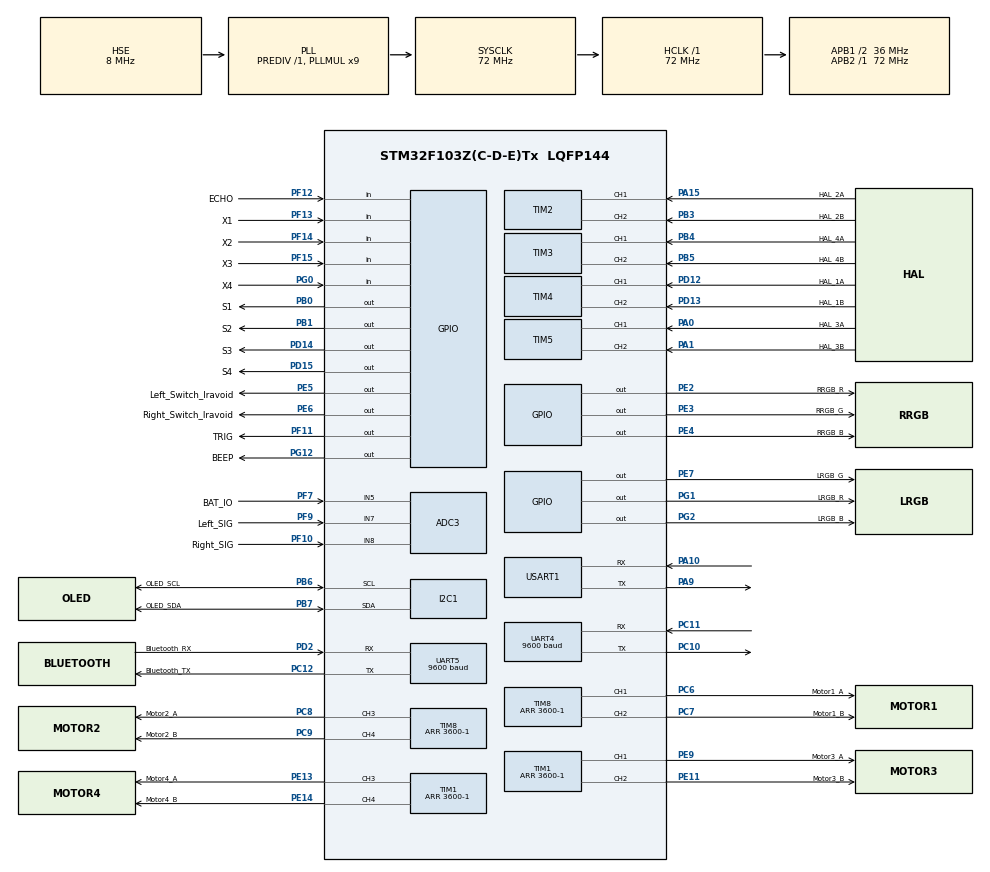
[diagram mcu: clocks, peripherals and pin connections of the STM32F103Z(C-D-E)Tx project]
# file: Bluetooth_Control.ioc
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ADC3.Channel-0\#ChannelRegularConversion=ADC_CHANNEL_5
ADC3.NbrOfConversionFlag=1
ADC3.Rank-0\#ChannelRegularConversion=1
ADC3.SamplingTime-0\#ChannelRegularConversion=ADC_SAMPLETIME_239CYCLES_5
Dma.Request0=USART1_TX
Dma.USART1_TX.0.Direction=DMA_MEMORY_TO_PERIPH
Dma.USART1_TX.0.Instance=DMA1_Channel4
Dma.USART1_TX.0.MemDataAlignment=DMA_MDATAALIGN_BYTE
Dma.USART1_TX.0.MemInc=DMA_MINC_ENABLE
Dma.USART1_TX.0.Mode=DMA_NORMAL
Dma.USART1_TX.0.PeriphDataAlignment=DMA_PDATAALIGN_BYTE
Dma.USART1_TX.0.PeriphInc=DMA_PINC_DISABLE
Dma.USART1_TX.0.Priority=DMA_PRIORITY_LOW
I2C1.I2C_Mode=I2C_Fast
Mcu.Family=STM32F1
Mcu.Name=STM32F103Z(C-D-E)Tx
Mcu.Package=LQFP144
NVIC.DMA1_Channel4_IRQn=true\:1\:0\:true\:false\:true\:false\:true\:true
NVIC.PriorityGroup=NVIC_PRIORITYGROUP_2
NVIC.TIM6_IRQn=true\:2\:1\:true\:false\:true\:true\:true\:true
NVIC.TIM7_IRQn=true\:2\:2\:true\:false\:true\:true\:true\:true
NVIC.UART4_IRQn=true\:1\:0\:true\:false\:true\:true\:true\:true
NVIC.UART5_IRQn=true\:1\:0\:true\:false\:true\:true\:true\:true
NVIC.USART1_IRQn=true\:1\:0\:true\:false\:true\:true\:true\:true
OSC_IN.Mode=HSE-External-Oscillator
OSC_IN.Signal=RCC_OSC_IN
OSC_OUT.Mode=HSE-External-Oscillator
OSC_OUT.Signal=RCC_OSC_OUT
PA0-WKUP.GPIO_Label=HAL_3A
PA0-WKUP.Signal=S_TIM5_CH1
PA1.GPIO_Label=HAL_3B
PA1.Signal=S_TIM5_CH2
PA10.Mode=Asynchronous
PA10.Signal=USART1_RX
PA13.Mode=Serial_Wire
PA13.Signal=SYS_JTMS-SWDIO
PA14.Mode=Serial_Wire
PA14.Signal=SYS_JTCK-SWCLK
PA15.GPIO_Label=HAL_2A
PA15.Signal=S_TIM2_CH1_ETR
PA9.Mode=Asynchronous
PA9.Signal=USART1_TX
PB0.GPIO_Label=S1
PB0.GPIO_Speed=GPIO_SPEED_FREQ_HIGH
PB0.Signal=GPIO_Output
PB1.GPIO_Label=S2
PB1.GPIO_Speed=GPIO_SPEED_FREQ_HIGH
PB1.Signal=GPIO_Output
PB3.GPIO_Label=HAL_2B
PB3.Signal=S_TIM2_CH2
PB4.GPIO_Label=HAL_4A
PB4.Signal=S_TIM3_CH1
PB5.GPIO_Label=HAL_4B
PB5.Signal=S_TIM3_CH2
PB6.GPIO_Label=OLED_SCL
PB6.Mode=I2C
PB6.Signal=I2C1_SCL
PB7.GPIO_Label=OLED_SDA
PB7.Mode=I2C
PB7.Signal=I2C1_SDA
PC10.Mode=Asynchronous
PC10.Signal=UART4_TX
PC11.Mode=Asynchronous
PC11.Signal=UART4_RX
PC12.GPIO_Label=Bluetooth_TX
PC12.Mode=Asynchronous
PC12.Signal=UART5_TX
PC6.GPIO_Label=Motor1_A
PC6.Signal=S_TIM8_CH1
PC7.GPIO_Label=Motor1_B
PC7.Signal=S_TIM8_CH2
PC8.GPIO_Label=Motor2_A
PC8.Signal=S_TIM8_CH3
PC9.GPIO_Label=Motor2_B
PC9.Signal=S_TIM8_CH4
PD12.GPIO_Label=HAL_1A
PD12.Signal=S_TIM4_CH1
PD13.GPIO_Label=HAL_1B
PD13.Signal=S_TIM4_CH2
PD14.GPIO_Label=S3
PD14.GPIO_Speed=GPIO_SPEED_FREQ_HIGH
PD14.Signal=GPIO_Output
PD15.GPIO_Label=S4
PD15.GPIO_Speed=GPIO_SPEED_FREQ_HIGH
PD15.Signal=GPIO_Output
PD2.GPIO_Label=Bluetooth_RX
PD2.Mode=Asynchronous
PD2.Signal=UART5_RX
PE11.GPIO_Label=Motor3_B
PE11.Signal=S_TIM1_CH2
PE13.GPIO_Label=Motor4_A
PE13.Signal=S_TIM1_CH3
PE14.GPIO_Label=Motor4_B
PE14.Signal=S_TIM1_CH4
PE2.GPIO_Label=RRGB_R
PE2.GPIO_Speed=GPIO_SPEED_FREQ_MEDIUM
PE2.Signal=GPIO_Output
PE3.GPIO_Label=RRGB_G
PE3.GPIO_Speed=GPIO_SPEED_FREQ_MEDIUM
PE3.Signal=GPIO_Output
PE4.GPIO_Label=RRGB_B
PE4.GPIO_Speed=GPIO_SPEED_FREQ_MEDIUM
PE4.Signal=GPIO_Output
PE5.GPIO_Label=Left_Switch_Iravoid
PE5.GPIO_Speed=GPIO_SPEED_FREQ_MEDIUM
PE5.PinState=GPIO_PIN_SET
PE5.Signal=GPIO_Output
PE6.GPIO_Label=Right_Switch_Iravoid
PE6.GPIO_Speed=GPIO_SPEED_FREQ_MEDIUM
PE6.PinState=GPIO_PIN_SET
PE6.Signal=GPIO_Output
PE7.GPIO_Label=LRGB_G
PE7.GPIO_Speed=GPIO_SPEED_FREQ_MEDIUM
PE7.Signal=GPIO_Output
PE9.GPIO_Label=Motor3_A
PE9.Signal=S_TIM1_CH1
PF10.GPIO_Label=Right_SIG
PF10.Mode=IN8
PF10.Signal=ADC3_IN8
PF11.GPIO_Label=TRIG
PF11.GPIO_Speed=GPIO_SPEED_FREQ_MEDIUM
PF11.Signal=GPIO_Output
PF12.GPIO_Label=ECHO
PF12.Signal=GPIO_Input
PF13.GPIO_Label=X1
PF13.Signal=GPIO_Input
PF14.GPIO_Label=X2
PF14.Signal=GPIO_Input
PF15.GPIO_Label=X3
PF15.Signal=GPIO_Input
PF7.GPIO_Label=BAT_IO
PF7.Mode=IN5
PF7.Signal=ADC3_IN5
PF9.GPIO_Label=Left_SIG
PF9.Mode=IN7
PF9.Signal=ADC3_IN7
PG0.GPIO_Label=X4
PG0.Signal=GPIO_Input
PG1.GPIO_Label=LRGB_R
PG1.GPIO_Speed=GPIO_SPEED_FREQ_MEDIUM
PG1.Signal=GPIO_Output
PG12.GPIO_Label=BEEP
PG12.GPIO_Speed=GPIO_SPEED_FREQ_MEDIUM
PG12.Signal=GPIO_Output
PG2.GPIO_Label=LRGB_B
PG2.GPIO_Speed=GPIO_SPEED_FREQ_MEDIUM
PG2.Signal=GPIO_Output
ProjectManager.HeapSize=0x200
ProjectManager.StackSize=0x400
ProjectManager.TargetToolchain=STM32CubeIDE
RCC.ADCPresc=RCC_ADCPCLK2_DIV6
RCC.AHBFreq_Value=72000000
RCC.APB1CLKDivider=RCC_HCLK_DIV2
RCC.APB1Freq_Value=36000000
RCC.APB1TimFreq_Value=72000000
RCC.APB2Freq_Value=72000000
RCC.APB2TimFreq_Value=72000000
RCC.HCLKFreq_Value=72000000
RCC.PLLMUL=RCC_PLL_MUL9
RCC.PLLSourceVirtual=RCC_PLLSOURCE_HSE
RCC.SYSCLKFreq_VALUE=72000000
RCC.SYSCLKSource=RCC_SYSCLKSOURCE_PLLCLK
RCC.USBFreq_Value=72000000
SH.S_TIM1_CH1.0=TIM1_CH1,PWM Generation1 CH1
SH.S_TIM1_CH2.0=TIM1_CH2,PWM Generation2 CH2
SH.S_TIM1_CH3.0=TIM1_CH3,PWM Generation3 CH3
SH.S_TIM1_CH4.0=TIM1_CH4,PWM Generation4 CH4
SH.S_TIM2_CH1_ETR.0=TIM2_CH1,Encoder_Interface
SH.S_TIM2_CH2.0=TIM2_CH2,Encoder_Interface
SH.S_TIM3_CH1.0=TIM3_CH1,Encoder_Interface
SH.S_TIM3_CH2.0=TIM3_CH2,Encoder_Interface
SH.S_TIM4_CH1.0=TIM4_CH1,Encoder_Interface
SH.S_TIM4_CH2.0=TIM4_CH2,Encoder_Interface
SH.S_TIM5_CH1.0=TIM5_CH1,Encoder_Interface
SH.S_TIM5_CH2.0=TIM5_CH2,Encoder_Interface
SH.S_TIM8_CH1.0=TIM8_CH1,PWM Generation1 CH1
SH.S_TIM8_CH2.0=TIM8_CH2,PWM Generation2 CH2
SH.S_TIM8_CH3.0=TIM8_CH3,PWM Generation3 CH3
SH.S_TIM8_CH4.0=TIM8_CH4,PWM Generation4 CH4
TIM1.AutoReloadPreload=TIM_AUTORELOAD_PRELOAD_ENABLE
TIM1.Channel-PWM\ Generation1\ CH1=TIM_CHANNEL_1
TIM1.Channel-PWM\ Generation2\ CH2=TIM_CHANNEL_2
TIM1.Channel-PWM\ Generation3\ CH3=TIM_CHANNEL_3
TIM1.Channel-PWM\ Generation4\ CH4=TIM_CHANNEL_4
TIM1.Period=3600-1
TIM2.EncoderMode=TIM_ENCODERMODE_TI12
TIM3.EncoderMode=TIM_ENCODERMODE_TI12
TIM4.EncoderMode=TIM_ENCODERMODE_TI12
TIM5.EncoderMode=TIM_ENCODERMODE_TI12
TIM6.Period=99
TIM6.Prescaler=7199
TIM7.Period=9
TIM7.Prescaler=71
TIM8.AutoReloadPreload=TIM_AUTORELOAD_PRELOAD_ENABLE
TIM8.Channel-PWM\ Generation1\ CH1=TIM_CHANNEL_1
TIM8.Channel-PWM\ Generation2\ CH2=TIM_CHANNEL_2
TIM8.Channel-PWM\ Generation3\ CH3=TIM_CHANNEL_3
TIM8.Channel-PWM\ Generation4\ CH4=TIM_CHANNEL_4
TIM8.Period=3600-1
UART4.BaudRate=9600
UART4.VirtualMode=Asynchronous
UART5.BaudRate=9600
UART5.VirtualMode=Asynchronous
USART1.VirtualMode=VM_ASYNC
VP_TIM1_VS_ClockSourceINT.Mode=Internal
VP_TIM6_VS_ClockSourceINT.Mode=Enable_Timer
VP_TIM7_VS_ClockSourceINT.Mode=Enable_Timer
VP_TIM8_VS_ClockSourceINT.Mode=Internal
board=custom

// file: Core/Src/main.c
/* USER CODE BEGIN Header */
/**
  ******************************************************************************
  * @file           : main.c
  * @brief          : Main program body
  ******************************************************************************
  * @attention
  *
  * <h2><center>&copy; Copyright (c) 2023 STMicroelectronics.
  * All rights reserved.</center></h2>
  *
  * This software component is licensed by ST under BSD 3-Clause license,
  * the "License"; You may not use this file except in compliance with the
  * License. You may obtain a copy of the License at:
  *                        opensource.org/licenses/BSD-3-Clause
  *
  ******************************************************************************
  */
/* USER CODE END Header */
#include "main.h"
#include "adc.h"
#include "dma.h"
#include "i2c.h"
#include "tim.h"
#include "usart.h"
#include "gpio.h"

/* USER CODE BEGIN Includes */
#include "bsp.h"
/* USER CODE END Includes */

void SystemClock_Config(void);

int main(void)
{

  /* USER CODE BEGIN 1 */
  /*
   * 上电第一件事: �? PC10 (UART4_TX, 连接 IMU RX) 拉高�?
   * 如果 PC10 浮空�? LOW, IMU �? RX 引脚会收到持续低电平,
   * 导致 IMU 进入 bootloader 模式而非正常运行 (LED 不闪, 不发送数�?)�?
   * 必须先开 GPIOC 时钟, 配为推挽输出, �? BSRR 置高�?
   */
  RCC->APB2ENR |= RCC_APB2ENR_IOPCEN;
  GPIOC->CRH &= ~(0xF << 8);        /* �? PC10 配置�? */
  GPIOC->CRH |=  (0x3 << 8);        /* PC10 = 50MHz 推挽输出 */
  GPIOC->BSRR  =  (1U << 10);       /* 置高 PC10 */
  /* USER CODE END 1 */

  /* MCU Configuration--------------------------------------------------------*/

  /* Reset of all peripherals, Initializes the Flash interface and the Systick. */
  HAL_Init();

  /* Configure the system clock */
  SystemClock_Config();

  /* Initialize all configured peripherals */
  MX_GPIO_Init();
  MX_DMA_Init();
  MX_TIM1_Init();
  MX_TIM2_Init();
  MX_TIM3_Init();
  MX_TIM4_Init();
  MX_TIM5_Init();
  MX_TIM6_Init();
  MX_TIM8_Init();
  MX_UART5_Init();
  MX_USART1_UART_Init();
  MX_I2C1_Init();
  MX_ADC3_Init();
  MX_TIM7_Init();
  MX_UART4_Init();
  /* USER CODE BEGIN 2 */
  BSP_Init();
  /* USER CODE END 2 */

  /* Infinite loop */
  while (1)
  {

    /* USER CODE BEGIN 3 */
	  BSP_Loop();
  }
  /* USER CODE END 3 */
}

void SystemClock_Config(void)
{
  RCC_OscInitTypeDef RCC_OscInitStruct = {0};
  RCC_ClkInitTypeDef RCC_ClkInitStruct = {0};
  RCC_PeriphCLKInitTypeDef PeriphClkInit = {0};

  /** Initializes the RCC Oscillators according to the specified parameters
  * in the RCC_OscInitTypeDef structure.
  */
  RCC_OscInitStruct.OscillatorType = RCC_OSCILLATORTYPE_HSE;
  RCC_OscInitStruct.HSEState = RCC_HSE_ON;
  RCC_OscInitStruct.HSEPredivValue = RCC_HSE_PREDIV_DIV1;
  RCC_OscInitStruct.HSIState = RCC_HSI_ON;
  RCC_OscInitStruct.PLL.PLLState = RCC_PLL_ON;
  RCC_OscInitStruct.PLL.PLLSource = RCC_PLLSOURCE_HSE;
  RCC_OscInitStruct.PLL.PLLMUL = RCC_PLL_MUL9;
  if (HAL_RCC_OscConfig(&RCC_OscInitStruct) != HAL_OK)
  {
    Error_Handler();
  }

  /** Initializes the CPU, AHB and APB buses clocks
  */
  RCC_ClkInitStruct.ClockType = RCC_CLOCKTYPE_HCLK|RCC_CLOCKTYPE_SYSCLK
                              |RCC_CLOCKTYPE_PCLK1|RCC_CLOCKTYPE_PCLK2;
  RCC_ClkInitStruct.SYSCLKSource = RCC_SYSCLKSOURCE_PLLCLK;
  RCC_ClkInitStruct.AHBCLKDivider = RCC_SYSCLK_DIV1;
  RCC_ClkInitStruct.APB1CLKDivider = RCC_HCLK_DIV2;
  RCC_ClkInitStruct.APB2CLKDivider = RCC_HCLK_DIV1;

  if (HAL_RCC_ClockConfig(&RCC_ClkInitStruct, FLASH_LATENCY_2) != HAL_OK)
  {
    Error_Handler();
  }
  PeriphClkInit.PeriphClockSelection = RCC_PERIPHCLK_ADC;
  PeriphClkInit.AdcClockSelection = RCC_ADCPCLK2_DIV6;
  if (HAL_RCCEx_PeriphCLKConfig(&PeriphClkInit) != HAL_OK)
  {
    Error_Handler();
  }
}

void Error_Handler(void)
{
  __disable_irq();
  while (1)
  {
  }
}
